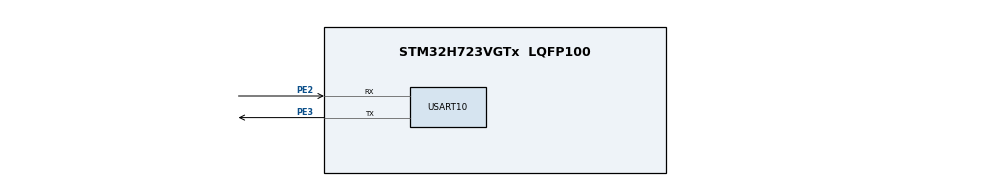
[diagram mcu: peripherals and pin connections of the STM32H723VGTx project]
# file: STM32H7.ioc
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CORTEX_M7.default_mode_Activation=1
Dma.Request0=USART10_RX
Dma.USART10_RX.0.Direction=DMA_PERIPH_TO_MEMORY
Dma.USART10_RX.0.EventEnable=DISABLE
Dma.USART10_RX.0.FIFOMode=DMA_FIFOMODE_DISABLE
Dma.USART10_RX.0.Instance=DMA1_Stream0
Dma.USART10_RX.0.MemDataAlignment=DMA_MDATAALIGN_BYTE
Dma.USART10_RX.0.MemInc=DMA_MINC_ENABLE
Dma.USART10_RX.0.Mode=DMA_NORMAL
Dma.USART10_RX.0.PeriphDataAlignment=DMA_PDATAALIGN_BYTE
Dma.USART10_RX.0.PeriphInc=DMA_PINC_DISABLE
Dma.USART10_RX.0.Polarity=HAL_DMAMUX_REQ_GEN_RISING
Dma.USART10_RX.0.Priority=DMA_PRIORITY_MEDIUM
Dma.USART10_RX.0.RequestNumber=1
Dma.USART10_RX.0.SignalID=NONE
Dma.USART10_RX.0.SyncEnable=DISABLE
Dma.USART10_RX.0.SyncPolarity=HAL_DMAMUX_SYNC_NO_EVENT
Dma.USART10_RX.0.SyncRequestNumber=1
Dma.USART10_RX.0.SyncSignalID=NONE
Mcu.Family=STM32H7
Mcu.Name=STM32H723VGTx
Mcu.Package=LQFP100
NVIC.DMA1_Stream0_IRQn=true\:0\:0\:false\:false\:true\:false\:true\:true
NVIC.PriorityGroup=NVIC_PRIORITYGROUP_4
NVIC.TIM1_UP_IRQn=true\:15\:0\:false\:false\:true\:false\:true\:true
NVIC.TimeBase=TIM1_UP_IRQn
NVIC.TimeBaseIP=TIM1
NVIC.USART10_IRQn=true\:0\:0\:false\:false\:true\:true\:true\:true
PE2.Mode=Asynchronous
PE2.Signal=USART10_RX
PE3.Mode=Asynchronous
PE3.Signal=USART10_TX
PH0-OSC_IN.Mode=HSE-External-Oscillator
PH0-OSC_IN.Signal=RCC_OSC_IN
PH1-OSC_OUT.Mode=HSE-External-Oscillator
PH1-OSC_OUT.Signal=RCC_OSC_OUT
ProjectManager.HeapSize=0x200
ProjectManager.StackSize=0x400
ProjectManager.TargetToolchain=CMake
RCC.ADCFreq_Value=48375000
RCC.APB1Freq_Value=120000000
RCC.APB2Freq_Value=120000000
RCC.APB3Freq_Value=120000000
RCC.APB4Freq_Value=120000000
RCC.CortexFreq_Value=480000000
RCC.D1PPRE=RCC_APB3_DIV2
RCC.D2PPRE1=RCC_APB1_DIV2
RCC.D2PPRE2=RCC_APB2_DIV2
RCC.D3PPRE=RCC_APB4_DIV2
RCC.DIVM1=2
RCC.DIVN1=40
RCC.DIVP1=1
RCC.HCLKFreq_Value=240000000
RCC.HPRE=RCC_HCLK_DIV2
RCC.HSE_VALUE=24000000
RCC.PLLFRACN=0
RCC.PLLSourceVirtual=RCC_PLLSOURCE_HSE
RCC.SYSCLKFreq_VALUE=480000000
RCC.SYSCLKSource=RCC_SYSCLKSOURCE_PLLCLK
RCC.USBFreq_Value=240000000
USART10.VirtualMode=VM_ASYNC
VP_MEMORYMAP_VS_MEMORYMAP.Mode=CurAppReg
VP_SYS_VS_tim1.Mode=TIM1
VP_TIM2_VS_ClockSourceINT.Mode=Internal
board=custom

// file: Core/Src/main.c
/* USER CODE BEGIN Header */
/**
  ******************************************************************************
  * @file           : main.c
  * @brief          : Main program body
  ******************************************************************************
  * @attention
  *
  * Copyright (c) 2026 STMicroelectronics.
  * All rights reserved.
  *
  * This software is licensed under terms that can be found in the LICENSE file
  * in the root directory of this software component.
  * If no LICENSE file comes with this software, it is provided AS-IS.
  *
  ******************************************************************************
  */
/* USER CODE END Header */
#include "main.h"
#include <string.h>
#define RX_BUF_SIZE 256

/* USER CODE BEGIN PD */
uint8_t r_data[RX_BUF_SIZE];
uint8_t remem[RX_BUF_SIZE];
volatile int flag = 0;
volatile int len;
/* USER CODE END PD */

TIM_HandleTypeDef htim2;

UART_HandleTypeDef huart10;
DMA_HandleTypeDef hdma_usart10_rx;

void SystemClock_Config(void);
static void MPU_Config(void);
static void MX_GPIO_Init(void);
static void MX_DMA_Init(void);
static void MX_TIM2_Init(void);
static void MX_USART10_UART_Init(void);

int main(void)
{

  /* USER CODE BEGIN 1 */
  uint8_t t1_data[] = "Hello!";
  uint8_t t2_data[] = "World!";
  /* USER CODE END 1 */

  /* MPU Configuration--------------------------------------------------------*/
  MPU_Config();

  /* MCU Configuration--------------------------------------------------------*/

  /* Reset of all peripherals, Initializes the Flash interface and the Systick. */
  HAL_Init();

  /* USER CODE BEGIN Init */
  HAL_UART_Receive_IT(&huart10, r_data, 8);
  /* USER CODE END Init */

  /* Configure the system clock */
  SystemClock_Config();

  /* Initialize all configured peripherals */
  MX_GPIO_Init();
  MX_DMA_Init();
  MX_TIM2_Init();
  MX_USART10_UART_Init();
  /* USER CODE BEGIN 2 */
  if (HAL_UARTEx_ReceiveToIdle_DMA(&huart10, r_data, 8) != HAL_OK) {
    Error_Handler();
  }

  __HAL_DMA_DISABLE_IT(huart10.hdmarx,DMA_IT_TE);
  /* USER CODE END 2 */

  /* Infinite loop */
  while (1) {

    /* USER CODE BEGIN 3 */
    HAL_UART_Transmit_IT(&huart10,t1_data, strlen((char*)t1_data));

    if (flag == 1) {
      flag = 0;
      HAL_UART_Transmit_IT(&huart10, t2_data, strlen((char*)t2_data));
      HAL_UART_Transmit_IT(&huart10, remem, strlen((char*)remem));
      memset(remem, 0, strlen((char*)remem));
      HAL_Delay(1000);
    }

    HAL_Delay(1000);
    /* USER CODE END 3 */
  }
}

void SystemClock_Config(void)
{
  RCC_OscInitTypeDef RCC_OscInitStruct = {0};
  RCC_ClkInitTypeDef RCC_ClkInitStruct = {0};

  /** Supply configuration update enable
  */
  HAL_PWREx_ConfigSupply(PWR_LDO_SUPPLY);

  /** Configure the main internal regulator output voltage
  */
  __HAL_PWR_VOLTAGESCALING_CONFIG(PWR_REGULATOR_VOLTAGE_SCALE0);

  while(!__HAL_PWR_GET_FLAG(PWR_FLAG_VOSRDY)) {}

  /** Initializes the RCC Oscillators according to the specified parameters
  * in the RCC_OscInitTypeDef structure.
  */
  RCC_OscInitStruct.OscillatorType = RCC_OSCILLATORTYPE_HSE;
  RCC_OscInitStruct.HSEState = RCC_HSE_ON;
  RCC_OscInitStruct.PLL.PLLState = RCC_PLL_ON;
  RCC_OscInitStruct.PLL.PLLSource = RCC_PLLSOURCE_HSE;
  RCC_OscInitStruct.PLL.PLLM = 2;
  RCC_OscInitStruct.PLL.PLLN = 40;
  RCC_OscInitStruct.PLL.PLLP = 1;
  RCC_OscInitStruct.PLL.PLLQ = 2;
  RCC_OscInitStruct.PLL.PLLR = 2;
  RCC_OscInitStruct.PLL.PLLRGE = RCC_PLL1VCIRANGE_3;
  RCC_OscInitStruct.PLL.PLLVCOSEL = RCC_PLL1VCOWIDE;
  RCC_OscInitStruct.PLL.PLLFRACN = 0;
  if (HAL_RCC_OscConfig(&RCC_OscInitStruct) != HAL_OK)
  {
    Error_Handler();
  }

  /** Initializes the CPU, AHB and APB buses clocks
  */
  RCC_ClkInitStruct.ClockType = RCC_CLOCKTYPE_HCLK|RCC_CLOCKTYPE_SYSCLK
                              |RCC_CLOCKTYPE_PCLK1|RCC_CLOCKTYPE_PCLK2
                              |RCC_CLOCKTYPE_D3PCLK1|RCC_CLOCKTYPE_D1PCLK1;
  RCC_ClkInitStruct.SYSCLKSource = RCC_SYSCLKSOURCE_PLLCLK;
  RCC_ClkInitStruct.SYSCLKDivider = RCC_SYSCLK_DIV1;
  RCC_ClkInitStruct.AHBCLKDivider = RCC_HCLK_DIV2;
  RCC_ClkInitStruct.APB3CLKDivider = RCC_APB3_DIV2;
  RCC_ClkInitStruct.APB1CLKDivider = RCC_APB1_DIV2;
  RCC_ClkInitStruct.APB2CLKDivider = RCC_APB2_DIV2;
  RCC_ClkInitStruct.APB4CLKDivider = RCC_APB4_DIV2;

  if (HAL_RCC_ClockConfig(&RCC_ClkInitStruct, FLASH_LATENCY_3) != HAL_OK)
  {
    Error_Handler();
  }
}

static void MX_TIM2_Init(void)
{

  TIM_ClockConfigTypeDef sClockSourceConfig = {0};
  TIM_MasterConfigTypeDef sMasterConfig = {0};

  htim2.Instance = TIM2;
  htim2.Init.Prescaler = 0;
  htim2.Init.CounterMode = TIM_COUNTERMODE_UP;
  htim2.Init.Period = 4294967295;
  htim2.Init.ClockDivision = TIM_CLOCKDIVISION_DIV1;
  htim2.Init.AutoReloadPreload = TIM_AUTORELOAD_PRELOAD_DISABLE;
  if (HAL_TIM_Base_Init(&htim2) != HAL_OK)
  {
    Error_Handler();
  }
  sClockSourceConfig.ClockSource = TIM_CLOCKSOURCE_INTERNAL;
  if (HAL_TIM_ConfigClockSource(&htim2, &sClockSourceConfig) != HAL_OK)
  {
    Error_Handler();
  }
  sMasterConfig.MasterOutputTrigger = TIM_TRGO_RESET;
  sMasterConfig.MasterSlaveMode = TIM_MASTERSLAVEMODE_DISABLE;
  if (HAL_TIMEx_MasterConfigSynchronization(&htim2, &sMasterConfig) != HAL_OK)
  {
    Error_Handler();
  }

}

static void MX_USART10_UART_Init(void)
{

  huart10.Instance = USART10;
  huart10.Init.BaudRate = 115200;
  huart10.Init.WordLength = UART_WORDLENGTH_8B;
  huart10.Init.StopBits = UART_STOPBITS_1;
  huart10.Init.Parity = UART_PARITY_NONE;
  huart10.Init.Mode = UART_MODE_TX_RX;
  huart10.Init.HwFlowCtl = UART_HWCONTROL_NONE;
  huart10.Init.OverSampling = UART_OVERSAMPLING_16;
  huart10.Init.OneBitSampling = UART_ONE_BIT_SAMPLE_DISABLE;
  huart10.Init.ClockPrescaler = UART_PRESCALER_DIV1;
  huart10.AdvancedInit.AdvFeatureInit = UART_ADVFEATURE_NO_INIT;
  if (HAL_UART_Init(&huart10) != HAL_OK)
  {
    Error_Handler();
  }
  if (HAL_UARTEx_SetTxFifoThreshold(&huart10, UART_TXFIFO_THRESHOLD_1_8) != HAL_OK)
  {
    Error_Handler();
  }
  if (HAL_UARTEx_SetRxFifoThreshold(&huart10, UART_RXFIFO_THRESHOLD_1_8) != HAL_OK)
  {
    Error_Handler();
  }
  if (HAL_UARTEx_DisableFifoMode(&huart10) != HAL_OK)
  {
    Error_Handler();
  }

}

static void MX_DMA_Init(void)
{

  /* DMA controller clock enable */
  __HAL_RCC_DMA1_CLK_ENABLE();

  /* DMA interrupt init */
  /* DMA1_Stream0_IRQn interrupt configuration */
  HAL_NVIC_SetPriority(DMA1_Stream0_IRQn, 0, 0);
  HAL_NVIC_EnableIRQ(DMA1_Stream0_IRQn);

}

static void MX_GPIO_Init(void)
{

  /* GPIO Ports Clock Enable */
  __HAL_RCC_GPIOE_CLK_ENABLE();
  __HAL_RCC_GPIOH_CLK_ENABLE();

}

/* USER CODE BEGIN 4 */
void HAL_UARTEx_RxEventCallback(UART_HandleTypeDef* huart,uint16_t Size) {
  if (huart->Instance == USART10) {
    if (Size >= 5) {
      memset(remem,0,sizeof(remem));
      memcpy(remem,r_data,Size);
      memset(r_data,0,sizeof(r_data));
      flag = 1;
    }
    HAL_UARTEx_ReceiveToIdle_DMA(&huart10,r_data,sizeof(r_data));
  }
}
/* USER CODE END 4 */

 /* MPU Configuration */

void MPU_Config(void)
{
  MPU_Region_InitTypeDef MPU_InitStruct = {0};

  /* Disables the MPU */
  HAL_MPU_Disable();

  /** Initializes and configures the Region and the memory to be protected
  */
  MPU_InitStruct.Enable = MPU_REGION_ENABLE;
  MPU_InitStruct.Number = MPU_REGION_NUMBER0;
  MPU_InitStruct.BaseAddress = 0x0;
  MPU_InitStruct.Size = MPU_REGION_SIZE_4GB;
  MPU_InitStruct.SubRegionDisable = 0x87;
  MPU_InitStruct.TypeExtField = MPU_TEX_LEVEL0;
  MPU_InitStruct.AccessPermission = MPU_REGION_NO_ACCESS;
  MPU_InitStruct.DisableExec = MPU_INSTRUCTION_ACCESS_DISABLE;
  MPU_InitStruct.IsShareable = MPU_ACCESS_SHAREABLE;
  MPU_InitStruct.IsCacheable = MPU_ACCESS_NOT_CACHEABLE;
  MPU_InitStruct.IsBufferable = MPU_ACCESS_NOT_BUFFERABLE;

  HAL_MPU_ConfigRegion(&MPU_InitStruct);
  /* Enables the MPU */
  HAL_MPU_Enable(MPU_PRIVILEGED_DEFAULT);

}

void HAL_TIM_PeriodElapsedCallback(TIM_HandleTypeDef *htim)
{
  if (htim->Instance == TIM1)
  {
    HAL_IncTick();
  }
}

void Error_Handler(void)
{
    __disable_irq();
    while (1)
    {
    }
}
